# S32K324_M7 register map
Vendor: NXP Semiconductors; File version: 1.1
CPU: CM7 r0p1, little endian, MPU, FPU, VTOR, 4 interrupt priority bits
Registers are 32-bit, read-write, reset 0x0 unless marked. A register's access mark holds for its fields unless they carry their own. Offsets are from the block's base; [hi:lo] are bit positions; {n}, {i} and the like mark numbered series; 'fields as' and 'values as' point back to an identical list.

## ADC_0 — ADC
Base 0x400A0000
Same registers: ADC_1 0x400A4000
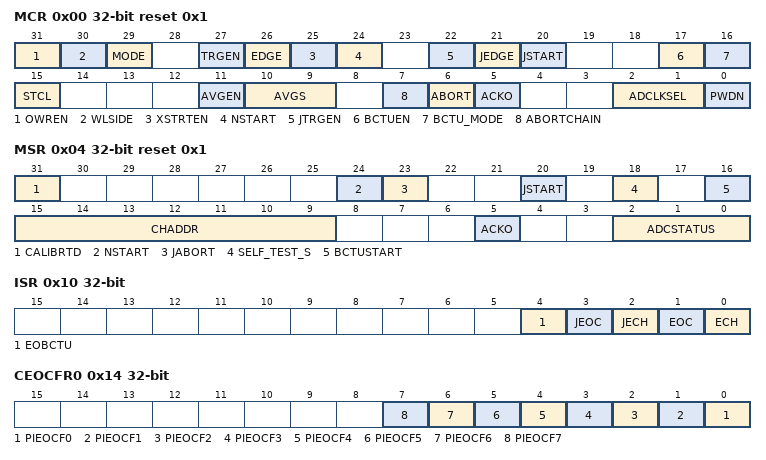
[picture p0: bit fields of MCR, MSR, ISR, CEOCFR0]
0x00 MCR reset 0x1 — Main Configuration
  [31] OWREN — Overwrite Enable
    0=noovwr (Disable); 1=enovwr (Enable)
  [30] WLSIDE — Write Left-Aligned
    0=rightaligned; 1=leftaligned
  [29] MODE — Normal Conversion Mode
    0=once (Single conversion); 1=Continuous conversion
  [27] TRGEN — External Trigger Enable
    0=noexttrg (Normal trigger input does not start a conversion); 1=enexttrg (Normal trigger input starts a conversion)
  [26] EDGE — External Trigger Edge Selection
    0=fedge (Falling edge); 1=redge (Rising edge)
  [25] XSTRTEN — Auxiliary External Start Enable
    0=noextstart (Disable); 1=enextstart (Enable)
  [24] NSTART — Start Normal Conversion
    0=nonstart (No effect); 1=donstart (Starts conversion)
  [22] JTRGEN — Injection Trigger Enable
    0=noj (Disable); 1=enj (Enable)
  [21] JEDGE — Injected Trigger Edge Selection
    0=fjedge (Falling edge); 1=rjedge (Rising edge)
  [20] JSTART — Injected Start
    0=noj (Injected conversion can be started); 1=doj (Starts an injected conversion)
  [17] BCTUEN — Body Cross Trigger Unit Enable
    0=noctu (Disable); 1=enctu (Enable)
  [16] BCTU_MODE — Body Cross Trigger Unit Mode Select
    0=ctuonly (Only BCTU can trigger conversion); 1=All trigger sources can trigger conversion
  [15] STCL write-once — Self-Test Configuration Lock
    0=noprotect (Registers are writeable); 1=doprotect (Registers are read-only)
  [11] AVGEN — Averaging Enable
    0=noavg (Disable); 1=enavg (Enable)
  [10:9] AVGS — Averaging Select
    0=4 conversions; 1=8 conversions; 2=16 conversions; 3=32 conversions
  [7] ABORTCHAIN write-1-clears
    on read: 0=UNDEFINED | on write: 1=ABORT_CHAIN_YES (Conversion aborted)
  [6] ABORT write-1-clears — Abort Conversion
    on read: 0=UNDEFINED | on write: 1=DO_ABORT (Conversion aborted)
  [5] ACKO — Auto Clock Off
    0=aclkoff (Clock always active); 1=aclkon (Clock gated)
  [2:1] ADCLKSEL — Conversion Clock (AD_clk) Frequency Selection
    0=disdiv (Module clock frequency); 1=div2 (Module clock frequency / 2); 2=div4 (Module clock frequency / 4); 3=div8 (Module clock frequency / 8)
  [0] PWDN — Power Down
    0=func (ADC enters a functional state); 1=pwdn (ADC enters Power Down state)
0x04 MSR ro reset 0x1 — Main Status
  [31] CALIBRTD — Calibration Status
    0=nocal (Uncalibrated or calibration unsuccessful); 1=cal (Calibrated)
  [24] NSTART — Normal Conversion Started
    0=non (Not in progress); 1=nrunning (In progress)
  [23] JABORT — Injected Conversion Aborted
    0=nojabort (Not aborted); 1=jaborted (Aborted)
  [20] JSTART — Injected Conversion Started
    0=noj (Not an injected conversion); 1=jrunning (Injected conversion)
  [18] SELF_TEST_S — Indicates whether an ongoing conversion is for self-test.
    0=nost (Not self-test); 1=strunning (Self-test)
  [16] BCTUSTART — BCTU Conversion Started
    0=ctuoff (Conversion was not triggered by BCTU); 1=cturunning (Ongoing conversion was triggered by BCTU)
  [15:9] CHADDR — Input Under Measure
    {v}=input_number (v=0..9)
  [5] ACKO — Auto Clock-Off On
    0=ackooff (Inactive); 1=ackoon (Active)
  [2:0] ADCSTATUS — ADC State
    0=idle; 1=powerdown; 2=wait; 3=calibrate; 4=convert; 6=done
0x10 ISR write-1-clears — Interrupt Status
  [4] EOBCTU write-1-clears — End Of BCTU Conversion
    on read: 0=EOBCTU_NO (No EOBCTU interrupt generated); 1=EOBCTU_YES (EOBCTU interrupt generated)
  [3] JEOC write-1-clears — End Of Injected Conversion
    on read: 0=JEOC_NO (No JEOC interrupt generated); 1=JEOC_YES (JEOC interrupt generated)
  [2] JECH write-1-clears — End Of Injected Chain Conversion
    on read: 0=JECH_NO (No JECH interrupt generated); 1=JECH_YES (JECH interrupt generated)
  [1] EOC write-1-clears — End Of Conversion
    on read: 0=EOC_NO (No EOC interrupt generated); 1=EOC_YES (Interrupt generated)
  [0] ECH write-1-clears — End Of Chain Conversion
    on read: 0=ECH_NO (Indicates no ECH interrupt generated); 1=ECH_YES (Indicates an ECH interrupt has been generated)
0x14 CEOCFR0 write-1-clears — Channel End Of Conversion Flag For Precision Inputs
  [all] fields
    on read: 0=COMPLETE_NO (Conversion not complete); 1=COMPLETE_YES (Conversion complete)
  [n] PIEOCF{n} write-1-clears (n=0..7) — Precision Input End Of Conversion Flag {n}
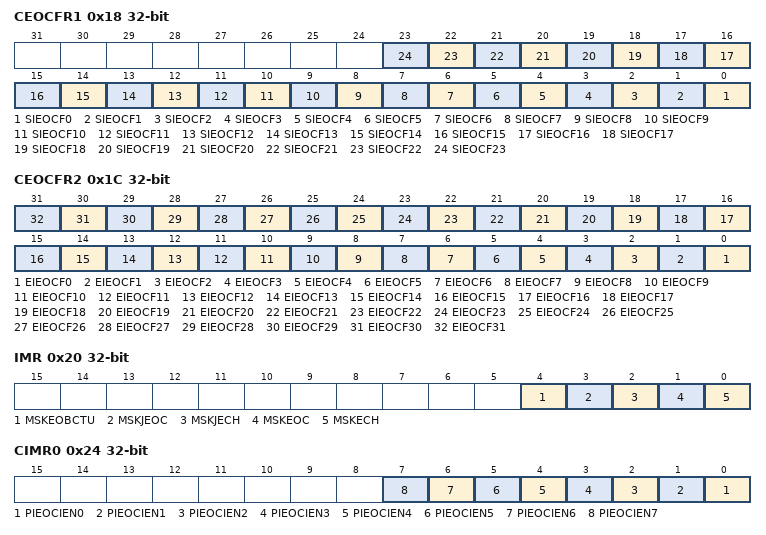
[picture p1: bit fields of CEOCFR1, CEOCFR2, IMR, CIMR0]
0x18 CEOCFR1 write-1-clears — Channel End Of Conversion Flag For Standard Inputs
  [all] fields
    values as the fields of CEOCFR0
  [n] SIEOCF{n} write-1-clears (n=0..23) — Standard Input End Of Conversion Flag
0x1C CEOCFR2 write-1-clears — Channel End Of Conversion Flag For External Inputs
  [all] fields
    values as the fields of CEOCFR0
  [n] EIEOCF{n} write-1-clears (n=0..31) — External Input End Of Conversion Flag
0x20 IMR — Interrupt Mask
  [4] MSKEOBCTU — EOBCTU Interrupt Flag Enable
    0=maskebctui (Interrupt is not flagged); 1=eneobctui (Interrupt is flagged)
  [3] MSKJEOC — JEOC Interrupt Flag Enable
    0=maskjeoci (Interrupt is not flagged); 1=enjeoci (Interrupt is flagged)
  [2] MSKJECH — JECH Interrupt Flag Enable
    0=maskjechi (Interrupt is not flagged); 1=enjechi (Interrupt is flagged)
  [1] MSKEOC — EOC Interrupt Flag Enable
    0=maskeoci (Interrupt is not flagged); 1=eneoci (Interrupt is flagged)
  [0] MSKECH — ECH Interrupt Flag Enable
    0=maskechi (Interrupt is not flagged); 1=enechi (Interrupt is flagged)
0x24 CIMR0 — EOC Interrupt Enable For Precision Inputs
  [all] fields
    0=nopieoci (Interrupt is not flagged); 1=pieociset (Interrupt is flagged)
  [n] PIEOCIEN{n} (n=0..7) — Precision Input EOC Interrupt Enable
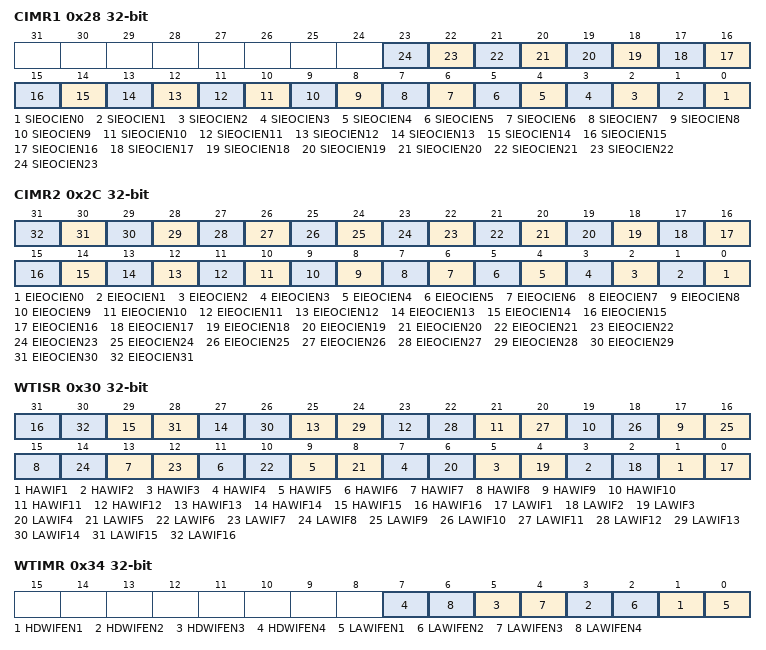
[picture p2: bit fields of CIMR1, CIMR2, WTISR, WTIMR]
0x28 CIMR1 — EOC Interrupt Enable For Standard Inputs
  [all] fields
    0=nosieoci (Interrupt is not flagged); 1=sieociset (Interrupt is flagged)
  [n] SIEOCIEN{n} (n=0..23) — Standard Input EOC Interrupt Enable
0x2C CIMR2 — EOC Interrupt Enable For External Inputs
  [all] fields
    0=noeieoci (Interrupt is not flagged); 1=eieociset (Interrupt is flagged)
  [n] EIEOCIEN{n} (n=0..31) — External Input EOC Interrupt Enable
0x30 WTISR write-1-clears — Analog Watchdog Threshold Interrupt Status
  [2n-1] HAWIF{n} write-1-clears (n=1..16) — High Analog Watchdog Interrupt Flag {n}
    on read: 0=LOWER (Conversion result is lower than the specified high threshold); 1=HIGHER (Conversion result is higher than the specified high threshold)
  [2n-2] LAWIF{n} write-1-clears (n=1..16) — Low Analog Watchdog Interrupt Flag {n}
    on read: 0=GREATER (Conversion result is greater than the specified low threshold); 1=LOWER (Conversion result is lower than the specified low threshold)
0x34 WTIMR — Analog Watchdog Threshold Interrupt Enable
  [2n-1] HDWIFEN{n} (n=1..4) — High Data Watchdog Interrupt Flag Enable n
    0=hwdgidis (Interrupt is not flagged); 1=hwdgien (Interrupt is flagged)
  [2n-2] LAWIFEN{n} (n=1..4) — Low Analog Watchdog Interrupt Flag Enable n
    0=lwdgidis (Interrupt is not flagged); 1=lwdgien (Interrupt is flagged)
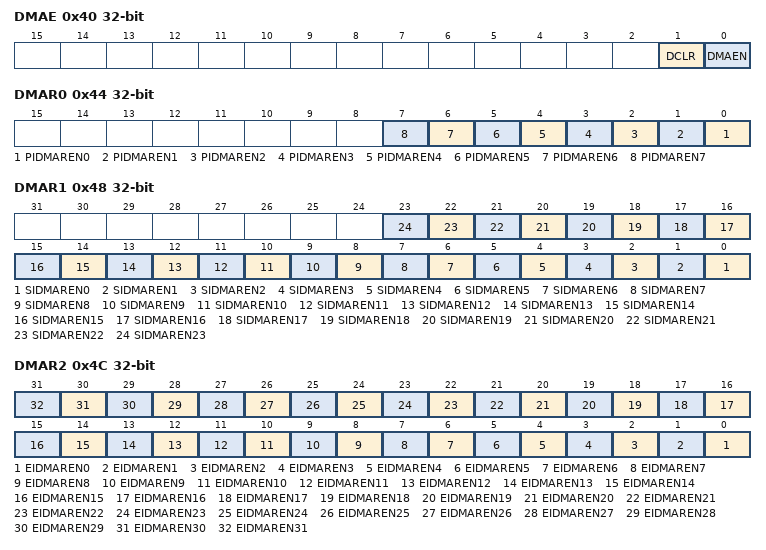
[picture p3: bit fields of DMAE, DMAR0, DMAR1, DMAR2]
0x40 DMAE — Direct Memory Access Configuration
  [1] DCLR — DMA Clear Request
    0=ackclr (DMA controller acknowledges the request); 1=ipsclr (Conversion data register is read)
  [0] DMAEN — DMA Enable
    0=dmadis (Disable); 1=dmaen (Enable)
0x44 DMAR0 — DMA Request Enable For Precision Inputs
  [all] fields
    0=nodmareq (Not triggered); 1=dmareqen (Triggered)
  [n] PIDMAREN{n} (n=0..7) — Precision Input DMA Request Enable {n}
0x48 DMAR1 — DMA Request Enable For Standard Inputs
  [all] fields
    0=nodmareq (DMA request is not triggered); 1=dmareqen (DMA is request triggered)
  [n] SIDMAREN{n} (n=0..23) — Standard Input DMA Request Enable n
0x4C DMAR2 — DMA Request Enable For External Inputs
  [all] fields
    0=nodmareq (DMA request is not triggered); 1=dmareqen (DMA request is triggered)
  [n] EIDMAREN{n} (n=0..31) — External Input DMA Request Enable n
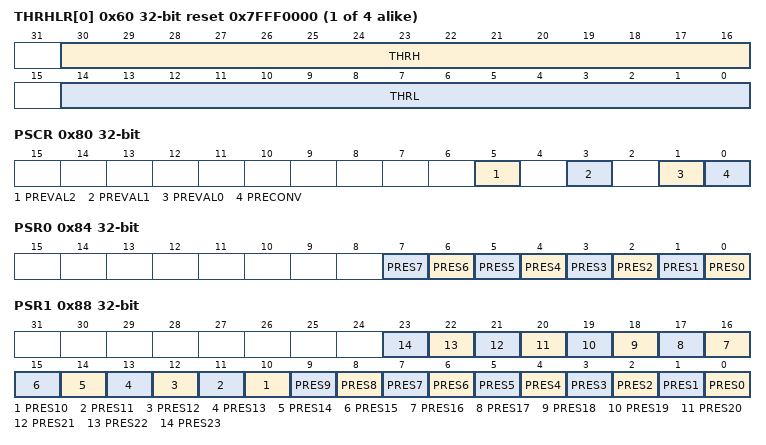
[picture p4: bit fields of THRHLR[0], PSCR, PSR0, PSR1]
{0x60+4i} THRHLR[{i}] (i=0..3) reset 0x7FFF0000 — Analog Watchdog Threshold Values
  [30:16] THRH — High Threshold Value
  [14:0] THRL — Low Threshold Value
0x80 PSCR — Presampling Control
  [5] PREVAL2 — Presampling Voltage Select For External Inputs
    0=lowpreval (VREFL); 1=highpreval (VREFH)
  [3] PREVAL1 — Presampling Voltage Select For Standard Inputs
    0=lowpreval (VREFL); 1=highpreval (VREFH)
  [1] PREVAL0 — Presampling Voltage Select For Precision Inputs
    0=lowpreval (VREFL); 1=highpreval (VREFH)
  [0] PRECONV — Convert Presampled Value
    0=nocomp (No conversion after presampling); 1=docomp (Presampling is followed by conversion)
0x84 PSR0 — Presampling Enable For Precision Inputs
  [all] fields
    0=nopre (Disable); 1=dopre (Enable)
  [n] PRES{n} (n=0..7) — Presampling Enable n
0x88 PSR1 — Presampling Enable For Standard Inputs
  [all] fields
    0=nopre (Disable); 1=dopre (Enable)
  [n] PRES{n} (n=0..23) — Presampling Enable n
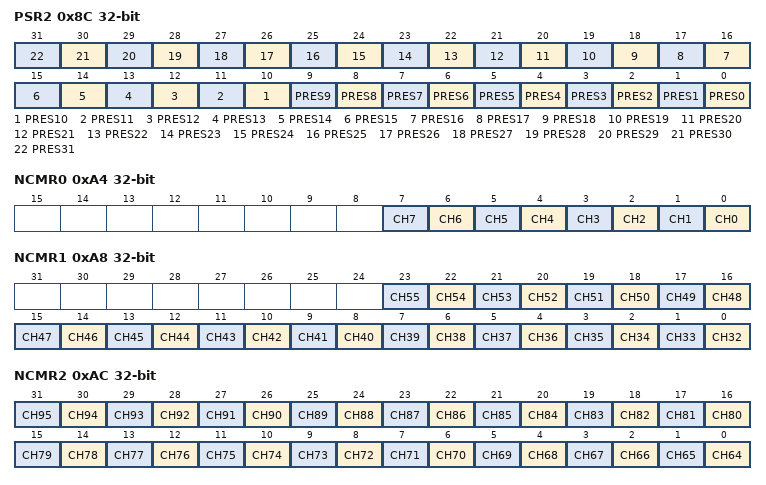
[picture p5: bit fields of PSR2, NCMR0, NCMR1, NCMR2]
0x8C PSR2 — Presampling Enable For External Inputs
  [all] fields
    0=nopre (Disable); 1=dopre (Enable)
  [n] PRES{n} (n=0..31) — Presampling Enable n
0x94 CTR0 reset 0x16 — Conversion Timing For Precision Inputs
  [7:0] INPSAMP — Input Sample Cycles
0x98 CTR1 reset 0x16 — Conversion Timing For Standard Inputs
  [7:0] INPSAMP — Input Sample Cycles
0x9C CTR2 reset 0x16 — Conversion Timing For External Inputs
  [7:0] INPSAMP — Input Sample Cycles
0xA4 NCMR0 — Normal Conversion Enable For Precision Inputs
  [all] fields
    0=nocon (Input is not selected); 1=docon (Input is selected)
  [n] CH{n} (n=0..7) — Precision Input To Be Converted
0xA8 NCMR1 — Normal Conversion Enable For Standard Inputs
  [all] fields
    0=nocon (Input n is not selected); 1=docon (Input n is selected)
  [n-32] CH{n} (n=32..55) — Standard Input To Be Converted
0xAC NCMR2 — Normal Conversion Enable For External Inputs
  [all] fields
    values as the fields of NCMR1
  [n-64] CH{n} (n=64..95) — External Input To Be Converted
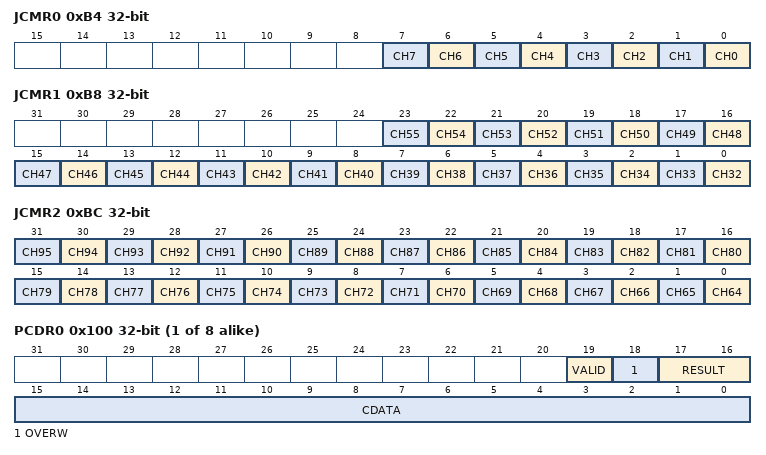
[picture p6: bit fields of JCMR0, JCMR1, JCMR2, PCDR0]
0xB4 JCMR0 — Injected Conversion Enable For Precision Inputs
  [n] CH{n} (n=0..7) — Precision Input To Be Converted
    0=nocon (Input {n} is not selected); 1=docon (Input {n} is selected)
0xB8 JCMR1 — Injected Conversion Enable For Standard Inputs
  fields as NCMR1
0xBC JCMR2 — Injected Conversion Enable For External Inputs
  fields as NCMR2
0xC4 DSDR — Delay Start Of Data Conversion
  [15:0] DSD — Delay
0xC8 PDEDR — Power Down Exit Delay
  [7:0] PDED — Delay
{0x100+4i} PCDR{i} ro (i=0..7) — Precision Input n Conversion Data
  [19] VALID — Conversion Data Available
    0=nodata (No unread conversion data); 1=dataav (Unread conversion data is available)
  [18] OVERW — Overwrite Status Flag
    0=noowr (No unread data is overwritten); 1=owr (Unread data is overwritten)
  [17:16] RESULT — Conversion Data Type
    0=ncd (Normal trigger); 1=jcd (Injected trigger); 2=bctucd (BCTU trigger)
  [15:0] CDATA — Conversion Data
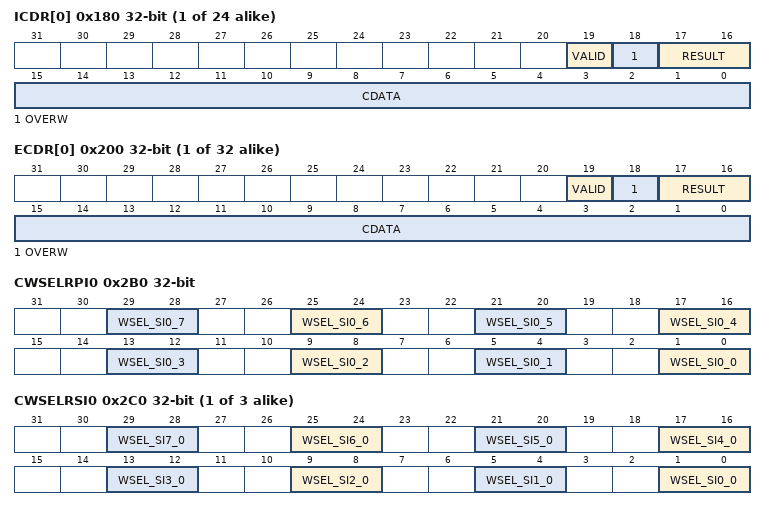
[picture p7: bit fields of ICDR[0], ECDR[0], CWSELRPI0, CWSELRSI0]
{0x180+4i} ICDR[{i}] (i=0..23) ro — Standard Input n Conversion Data
  fields as PCDR0
{0x200+4i} ECDR[{i}] (i=0..31) ro — External Input n Conversion Data
  fields as PCDR0
0x2B0 CWSELRPI0 — Channel Analog Watchdog Select For Precision Inputs
  [all] fields
    {v}=THRHLR{v} (Analog watchdog THRHLR{v}) (v=0..3)
  [4n+1:4n] WSEL_SI0_{n} (n=0..7) — Analog Watchdog Selection
0x2B4 CWSELRPI1 ro — Channel Analog Watchdog Select For Precision Inputs
{0x2C0+4i} CWSELRSI{i} (i=0..2) — Channel Analog Watchdog Select For Standard Inputs
  [all] fields
    {v}=THRHLR{v} (Analog watchdog THRHLR{v}) (v=0..3)
  [4n+1:4n] WSEL_SI{n}_{i} (n=0..7) — Analog Watchdog Selection
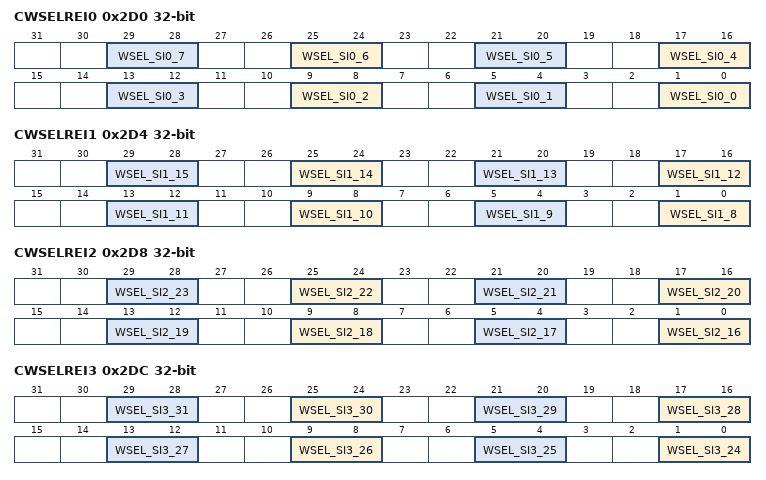
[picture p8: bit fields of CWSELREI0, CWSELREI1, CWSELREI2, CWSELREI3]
0x2D0 CWSELREI0 — Channel Analog Watchdog Select For External inputs
  fields as CWSELRPI0
0x2D4 CWSELREI1 — Channel Analog Watchdog Select For External inputs
  [all] fields
    {v}=THRHLR{v} (Analog watchdog THRHLR{v}) (v=0..3)
  [4n-31:4n-32] WSEL_SI1_{n} (n=8..15) — Analog Watchdog Selection
0x2D8 CWSELREI2 — Channel Analog Watchdog Select For External inputs
  [all] fields
    {v}=THRHLR{v} (Analog watchdog THRHLR{v}) (v=0..3)
  [4n-63:4n-64] WSEL_SI2_{n} (n=16..23) — Analog Watchdog Selection
0x2DC CWSELREI3 — Channel Analog Watchdog Select For External inputs
  [all] fields
    {v}=THRHLR{v} (Analog watchdog THRHLR{v}) (v=0..3)
  [4n-95:4n-96] WSEL_SI3_{n} (n=24..31) — Analog Watchdog Selection
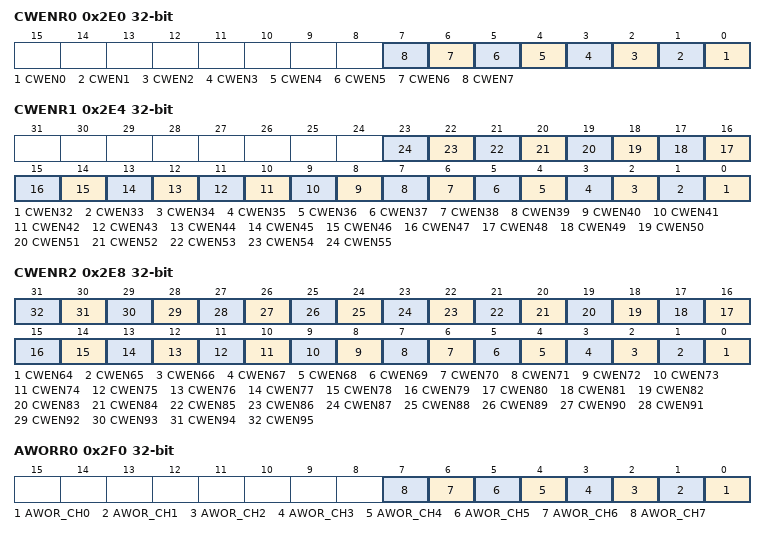
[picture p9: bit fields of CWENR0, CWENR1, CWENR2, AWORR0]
0x2E0 CWENR0 — Channel Watchdog Enable For Precision Inputs
  [all] fields
    0=nowd (Disable); 1=enwd (Enable)
  [n] CWEN{n} (n=0..7) — Channel Analog Watchdog Enable {n}
0x2E4 CWENR1 — Channel Watchdog Enable For Standard Inputs
  [all] fields
    0=nowd (Disable); 1=enwd (Enable)
  [n-32] CWEN{n} (n=32..55) — Channel Analog Watchdog Enable For Standard Inputs
0x2E8 CWENR2 — Channel Watchdog Enable For External Inputs
  [all] fields
    0=nowd (Disable); 1=enwd (Enable)
  [n-64] CWEN{n} (n=64..95) — Channel Analog Watchdog Enable For External Inputs
0x2F0 AWORR0 write-1-clears — Analog Watchdog Out Of Range For Precision Inputs
  [all] fields
    on read: 0=VALID_YES (Conversion is within limits); 1=VALID_NO (Conversion is not within limits)
  [n] AWOR_CH{n} write-1-clears (n=0..7) — Analog Watchdog Out Of Range For Precision Inputs
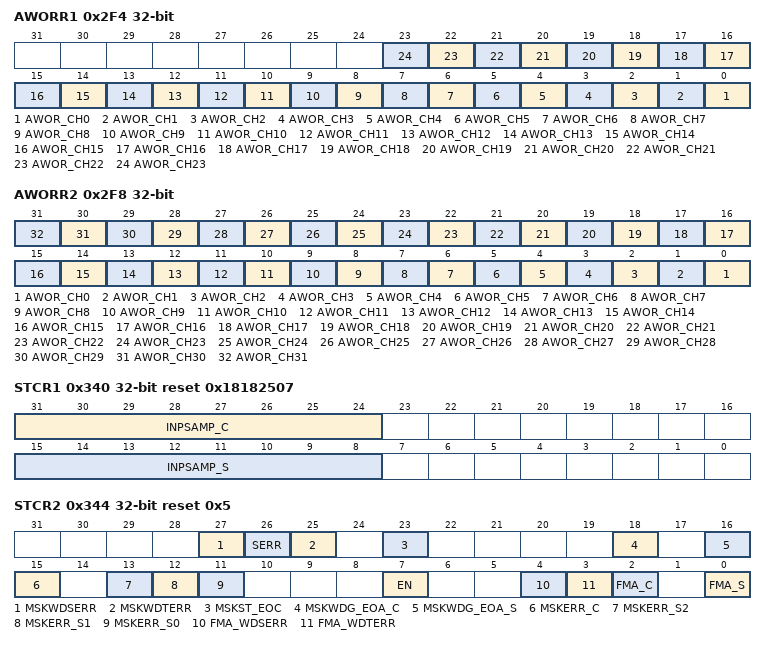
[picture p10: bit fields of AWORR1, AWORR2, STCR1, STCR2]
0x2F4 AWORR1 write-1-clears — Analog Watchdog Out Of Range For Standard Inputs
  [all] fields
    values as the fields of AWORR0
  [n] AWOR_CH{n} write-1-clears (n=0..23) — Analog Watchdog Out Of Range For Standard Inputs
0x2F8 AWORR2 write-1-clears — Analog Watchdog Out Of Range For External Inputs
  [all] fields
    values as the fields of AWORR0
  [n] AWOR_CH{n} write-1-clears (n=0..31) — Analog Watchdog Out Of Range For External Inputs
0x340 STCR1 reset 0x18182507 — Self-Test Configuration 1
  [31:24] INPSAMP_C — Input Sampling Time Algorithm C
  [15:8] INPSAMP_S — Input Sampling Time Algorithm S
0x344 STCR2 reset 0x5 — Self-Test Configuration 2
  [27] MSKWDSERR — Mask Interrupt Self-Test Watchdog Sequence Error
    0=idis (No interrupt is generated); 1=ien (Interrupt is generated)
  [26] SERR write-1-clears — Self-Test Error Injection
    on read: 0=INJ_AVAIL (Error can be injected); 1=INJ_NO (Error is being injected)
  [25] MSKWDTERR — Mask Interrupt Self-Test Watchdog Timer Error
    values as MSKWDSERR
  [23] MSKST_EOC — Mask Interrupt Self-Test End Of Conversion
    values as MSKWDSERR
  [18] MSKWDG_EOA_C — Mask Error Interrupt End Of Algorithm C
    values as MSKWDSERR
  [16] MSKWDG_EOA_S — Mask Error Interrupt End Of Algorithm S
    values as MSKWDSERR
  [15] MSKERR_C — Mask Error Interrupt Algorithm C
    values as MSKWDSERR
  [13] MSKERR_S2 — Mask Error Interrupt Algorithm S2
    values as MSKWDSERR
  [12] MSKERR_S1 — Mask Error Interrupt Algorithm S1
    values as MSKWDSERR
  [11] MSKERR_S0 — Mask Error Interrupt Algorithm S0
    values as MSKWDSERR
  [7] EN — Self-Test Enable
    0=stdis (Disable); 1=sten (Enable)
  [4] FMA_WDSERR — Fault Mapping Self-Test Watchdog Sequence Error
    0=ncf (Noncritical fault line); 1=cf (Critical fault line)
  [3] FMA_WDTERR — Fault Mapping Self-Test Watchdog Timer Error
    0=ncf (Noncritical fault line); 1=cf (Critical fault line)
  [2] FMA_C — Fault Mapping Algorithm C
    0=ncf (Noncritical fault line); 1=cf (Critical fault line)
  [0] FMA_S — Fault Mapping Algorithm S
    0=ncf (Noncritical fault line); 1=cf (Critical fault line)
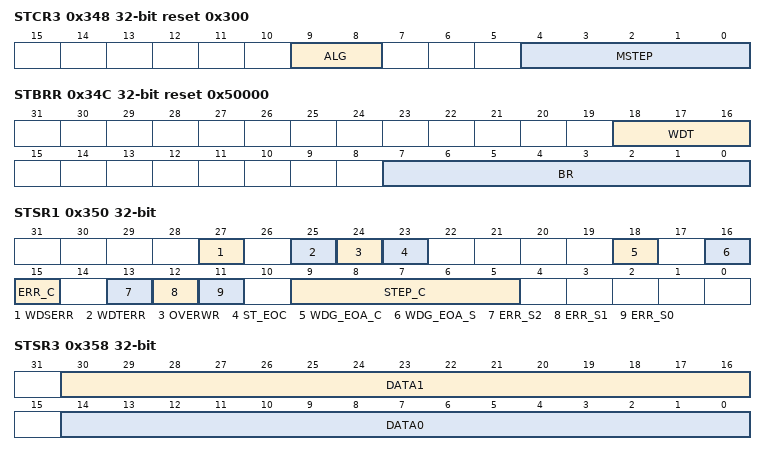
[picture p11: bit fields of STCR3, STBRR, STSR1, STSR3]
0x348 STCR3 reset 0x300 — Self-Test Configuration 3
  [9:8] ALG — Algorithm Selection
  [4:0] MSTEP — Algorithm Step
0x34C STBRR reset 0x50000 — Self-Test Baud Rate
  [18:16] WDT — Self-Test Watchdog Timer
    0=br0 (8192 conversion clock cycles (~0.1 ms at 80 MHz)); 1=br1 (39,936 conversion clock cycles (~0.5 ms at 80 MHz)); 2=br2 (79,872 conversion clock cycles (~1 ms at 80 MHz)); 3=br3 (159,744 conversion clock cycles (~2 ms at 80 MHz)); 4=br4 (400,384 conversion clock cycles (~5 ms at 80 MHz)); 5=br5 (799,744 conversion clock cycles (~10 ms at 80 MHz)); 6=br6 (1,599,488 conversion clock cycles (~20 ms at 80 MHz)); 7=br7 (3,999,744 conversion clock cycles (~50 ms at 80 MHz))
  [7:0] BR — Baud Rate
    0=fastestbr (A step of the selected self-test algorithm is executed every time after the set of selected inputs has been converted.); 255=slowestbr (A step of the selected self-test algorithm is executed after the set of selected inputs has been converted 256 times.)
0x350 STSR1 — Self-Test Status 1
  [27] WDSERR write-1-clears — Self-Test Watchdog Sequence Error
    on read: 0=WDSERR_NO (Algorithm executed in correct sequence); 1=WDSERR_YES (Algorithm did not execute in correct sequence)
  [25] WDTERR write-1-clears — Self-Test Watchdog Timer Error
    on read: 0=WDTERR_NO (Algorithm finished within the safe time period (or safe time period not yet elapsed).); 1=WDTERR_YES (Algorithm did not finish within safe time period.)
  [24] OVERWR write-1-clears — Self-Test Error Status Overwrite
    on read: 0=STOVRW_NO (No self-test error status flag overwritten); 1=STOVRW_YES (Self-test error status flag overwritten)
  [23] ST_EOC write-1-clears — Self-Test End Of Conversion
    on read: 0=STEOC_NO (Not complete); 1=STEOC_YES (Complete)
  [18] WDG_EOA_C write-1-clears — Self-Test Watchdog End Of Algorithm C
    on read: 0=COMPLETE_NO (Not complete); 1=COMPLETE_YES
  [16] WDG_EOA_S write-1-clears — Self-Test Watchdog End Of Algorithm S
    on read: 0=COMPLETE_NO (Not complete); 1=COMPLETE_YES
  [15] ERR_C write-1-clears — Error Algorithm C
    on read: 0=ERRC_NO (No error); 1=ERRC_YES (Error)
  [13] ERR_S2 write-1-clears — Error Algorithm S Step 2
    on read: 0=S2_ERR_NO (No error); 1=S2_ERR_YES (Error)
  [12] ERR_S1 write-1-clears — Error Algorithm S Step 1
    on read: 0=S1_ERR_NO (No error); 1=S1_ERR_YES (Error)
  [11] ERR_S0 write-1-clears — Error Algorithm S Step 0
    on read: 0=S0_ERR_NO (No error); 1=S0_ERR_YES (Error)
  [9:5] STEP_C ro — Step Of Algorithm C
0x354 STSR2 ro — Self-Test Status 2
  [14:0] DATA0 — Conversion Data ERR_S1
0x358 STSR3 ro — Self-Test Status 3
  [30:16] DATA1 — Conversion Data ERR_S2
  [14:0] DATA0 — Conversion Data ERR_S0
0x35C STSR4 ro — Self-Test Status 4
  [30:16] DATA1 — Conversion Data ERR_C
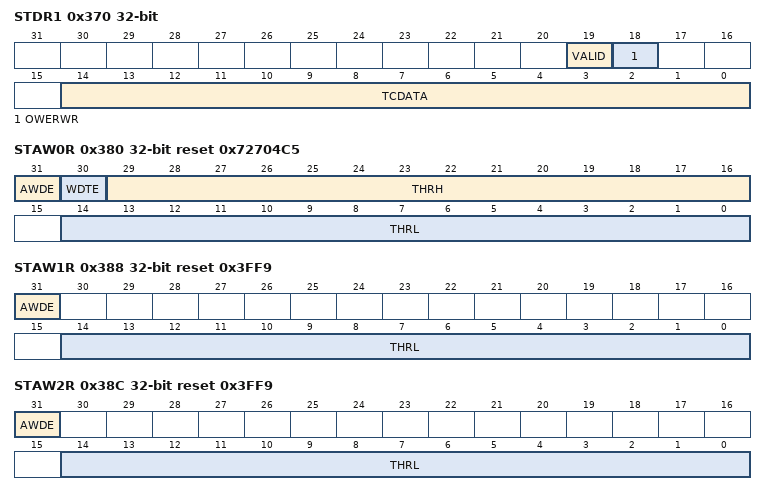
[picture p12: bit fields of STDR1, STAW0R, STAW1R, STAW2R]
0x370 STDR1 ro — Self-Test Conversion Data 1
  [19] VALID — Valid Conversion Data
    values as PCDR0.VALID
  [18] OWERWR — Conversion Data Overwrite Status
    0=noovwr (Current conversion data not overwritten); 1=ovwr (Current conversion data was overwritten)
  [14:0] TCDATA — Test Channel Conversion Data
0x380 STAW0R reset 0x72704C5 — Self-Test Analog Watchdog S0
  [31] AWDE — Self-Test Watchdog Enable
    0=diswd (Disable); 1=enwd (Enable)
  [30] WDTE — Self-Test Watchdog Timer Enable
    0=diswdt (Disable); 1=enwdt (Enable)
  [29:16] THRH — Higher Threshold Value
  [14:0] THRL — Lower Threshold Value
0x388 STAW1R reset 0x3FF9 — Self-Test Analog Watchdog S1
  [31] AWDE — Self-Test Watchdog Enable
    0=diswd (Disable); 1=enwd (Enable)
  [14:0] THRL — Lower Threshold Value
0x38C STAW2R reset 0x3FF9 — Self-Test Analog Watchdog S2
  fields as STAW1R
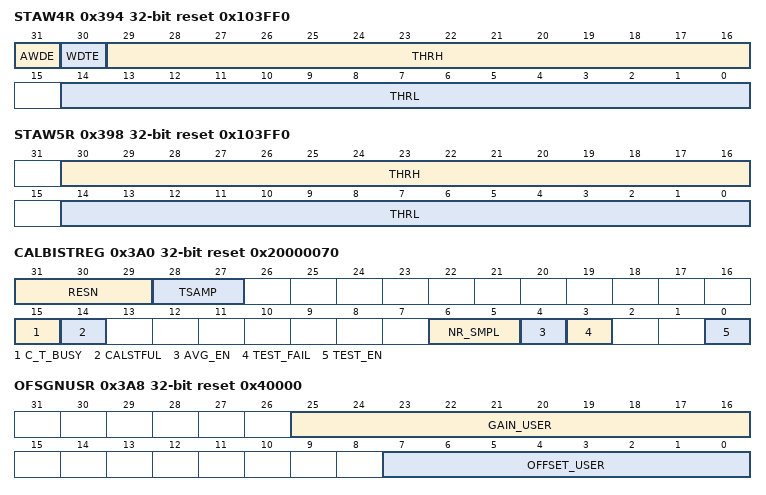
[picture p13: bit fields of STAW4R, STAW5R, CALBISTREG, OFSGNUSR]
0x394 STAW4R reset 0x103FF0 — Self-Test Analog Watchdog C0
  [31] AWDE — Self-Test Watchdog Enable
    0=noawc (Disable); 1=wdacen (Enable)
  [30] WDTE — Self-Test Watchdog Timer Enable
    0=stwdtdis (Disable); 1=stwdten (Enable)
  [29:16] THRH — Higher Threshold Value
  [14:0] THRL — Lower Threshold Value
0x398 STAW5R reset 0x103FF0 — Self-Test Analog Watchdog C
  [30:16] THRH — Higher Threshold Value
  [14:0] THRL — Lower Threshold Value
0x39C AMSIO reset 0x811 — Analog Miscellaneous In/Out register
  [18:17] HSEN — High-Speed Enable
    0=hsdisable (Normal conversion speed); 3=hsenable (High-speed conversion)
0x3A0 CALBISTREG reset 0x20000070 — Control And Calibration Status
  [31:29] RESN — Conversion Resolution
    0=high (14-bit resolution); 1=mid (12-bit resolution); 2=low (10-bit resolution); 3=lowest (8-bit resolution)
  [28:27] TSAMP — Sample Period In Calibration
    0=high (22 conversion clock cycles); 1=lowest (8 conversion clock cycles); 2=low (16 conversion clock cycles); 3=highest (32 conversion clock cycles)
  [15] C_T_BUSY ro — Calibration Busy
    0=waitcal (Calibration can be started); 1=runcal (Calibration is in progress)
  [14] CALSTFUL — Calibration And Self-Test Full Range Comparison
    0=reducedsar (Lowest 11 bits are compared.); 1=fullsar (All 15 bits are compared.)
  [6:5] NR_SMPL — Calibration Averaging Number
    0=lowest (4 samples); 1=low (8 samples); 2=high (16 samples); 3=highest (32 samples)
  [4] AVG_EN — Calibration Averaging Enable
    0=discalavg (Disable); 1=calav (Enable)
  [3] TEST_FAIL write-1-clears — Calibration Status
    on read: 0=CALPASS_YES (Calibration finished successfully or has not been run since the last reset); 1=CALPASS_NO (Calibration did not finish successfully)
  [0] TEST_EN — Calibration Enable
    0=nocal (Wait to start a calibration); 1=runcal (Start calibration)
0x3A8 OFSGNUSR reset 0x40000 — Offset And Gain User
  [25:16] GAIN_USER, [7:0] OFFSET_USER
0x3B4 CAL2 reset 0x43008243 — Calibration Value 2
  [15] ENX — Enable X
    0=disclpx (Disable); 1=enclpx (Enable)

## ADC_2 — ADC
Base 0x400A8000
Registers as ADC_0, without CEOCFR2, CIMR2, DMAR2, PSR2, CTR2, NCMR2, JCMR2, DSDR, ECDR[*], CWSELREI{n} (n=0..3), CWENR2, AWORR2; these are added or differ:
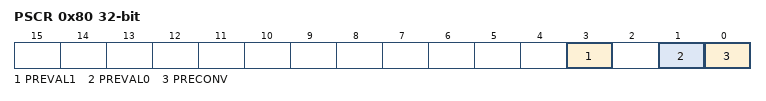
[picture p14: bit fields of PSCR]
0x80 PSCR — Presampling Control
  [3] PREVAL1 — Presampling Voltage Select For Standard Inputs
    0=lowpreval (VREFL); 1=highpreval (VREFH)
  [1] PREVAL0 — Presampling Voltage Select For Precision Inputs
    0=lowpreval (VREFL); 1=highpreval (VREFH)
  [0] PRECONV — Convert Presampled Value
    0=nocomp (No conversion after presampling); 1=docomp (Presampling is followed by conversion)
